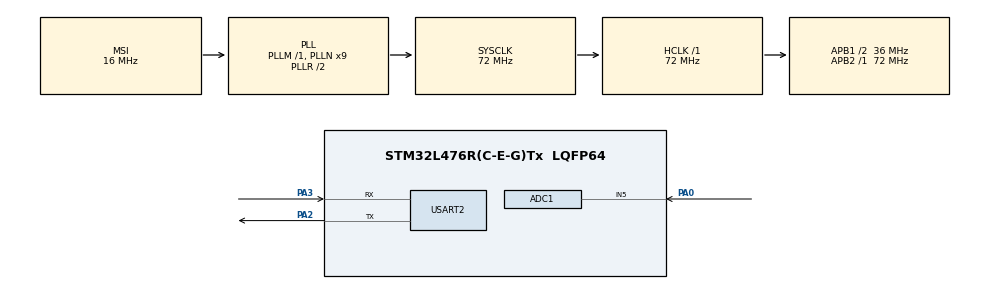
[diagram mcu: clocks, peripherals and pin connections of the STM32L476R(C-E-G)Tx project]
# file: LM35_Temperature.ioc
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ADC1.Channel-0\#ChannelRegularConversion=ADC_CHANNEL_5
ADC1.ClockPrescaler=ADC_CLOCK_ASYNC_DIV2
ADC1.NbrOfConversionFlag=1
ADC1.OffsetNumber-0\#ChannelRegularConversion=ADC_OFFSET_NONE
ADC1.Rank-0\#ChannelRegularConversion=1
ADC1.Resolution=ADC_RESOLUTION_10B
ADC1.SamplingTime-0\#ChannelRegularConversion=ADC_SAMPLETIME_2CYCLES_5
ADC1.master=1
Mcu.Family=STM32L4
Mcu.Name=STM32L476R(C-E-G)Tx
Mcu.Package=LQFP64
NVIC.PriorityGroup=NVIC_PRIORITYGROUP_4
PA0.Signal=ADCx_IN5
PA2.Mode=Asynchronous
PA2.Signal=USART2_TX
PA3.Mode=Asynchronous
PA3.Signal=USART2_RX
ProjectManager.HeapSize=0x200
ProjectManager.StackSize=0x400
ProjectManager.TargetToolchain=STM32CubeIDE
RCC.ADCFreq_Value=64000000
RCC.AHBFreq_Value=72000000
RCC.APB1CLKDivider=RCC_HCLK_DIV2
RCC.APB1Freq_Value=36000000
RCC.APB1TimFreq_Value=72000000
RCC.APB2Freq_Value=72000000
RCC.APB2TimFreq_Value=72000000
RCC.CortexFreq_Value=72000000
RCC.HCLKFreq_Value=72000000
RCC.HSE_VALUE=8000000
RCC.HSI_VALUE=16000000
RCC.LSE_VALUE=32768
RCC.MSIClockRange=RCC_MSIRANGE_8
RCC.MSI_VALUE=16000000
RCC.PLLN=9
RCC.SYSCLKFreq_VALUE=72000000
RCC.SYSCLKSource=RCC_SYSCLKSOURCE_PLLCLK
RCC.USBFreq_Value=64000000
RCC.VCOOutputFreq_Value=144000000
SH.ADCx_IN5.0=ADC1_IN5,IN5-Single-Ended
USART2.VirtualMode-Asynchronous=VM_ASYNC
board=custom

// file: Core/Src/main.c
/* USER CODE BEGIN Header */
/**
  ******************************************************************************
  * @file           : main.c
  * @brief          : Main program body
  ******************************************************************************
  * @attention
  *
  * Copyright (c) 2023 STMicroelectronics.
  * All rights reserved.
  *
  * This software is licensed under terms that can be found in the LICENSE file
  * in the root directory of this software component.
  * If no LICENSE file comes with this software, it is provided AS-IS.
  *
  ******************************************************************************
  */
/* USER CODE END Header */
#include "main.h"

/* USER CODE BEGIN Includes */
#include <stdio.h>
#include <string.h>
/* USER CODE END Includes */

ADC_HandleTypeDef hadc1;

UART_HandleTypeDef huart2;

/* USER CODE BEGIN PV */
uint32_t value_from_sensor = 0;
char log_message[120];
/* USER CODE END PV */

void SystemClock_Config(void);
static void MX_GPIO_Init(void);
static void MX_ADC1_Init(void);
static void MX_USART2_UART_Init(void);
/* USER CODE BEGIN PFP */
void convert_temperature_and_print(uint32_t value_to_convert);
/* USER CODE END PFP */

int main(void)
{

  /* MCU Configuration--------------------------------------------------------*/

  /* Reset of all peripherals, Initializes the Flash interface and the Systick. */
  HAL_Init();

  /* Configure the system clock */
  SystemClock_Config();

  /* Initialize all configured peripherals */
  MX_GPIO_Init();
  MX_ADC1_Init();
  MX_USART2_UART_Init();

  /* Infinite loop */
  /* USER CODE BEGIN WHILE */
  while (1)
  {
	if(HAL_ADC_Start(&hadc1) != HAL_OK) Error_Handler();
	if(HAL_ADC_PollForConversion(&hadc1, 20) != HAL_OK) Error_Handler();
	value_from_sensor = HAL_ADC_GetValue(&hadc1);
	HAL_ADC_Stop(&hadc1);
	if(value_from_sensor > 0)
	{
		convert_temperature_and_print(value_from_sensor);
	}
	HAL_Delay(1000);
    /* USER CODE END WHILE */

  }
}

void SystemClock_Config(void)
{
  RCC_OscInitTypeDef RCC_OscInitStruct = {0};
  RCC_ClkInitTypeDef RCC_ClkInitStruct = {0};

  /** Configure the main internal regulator output voltage
  */
  if (HAL_PWREx_ControlVoltageScaling(PWR_REGULATOR_VOLTAGE_SCALE1) != HAL_OK)
  {
    Error_Handler();
  }

  /** Initializes the RCC Oscillators according to the specified parameters
  * in the RCC_OscInitTypeDef structure.
  */
  RCC_OscInitStruct.OscillatorType = RCC_OSCILLATORTYPE_MSI;
  RCC_OscInitStruct.MSIState = RCC_MSI_ON;
  RCC_OscInitStruct.MSICalibrationValue = 0;
  RCC_OscInitStruct.MSIClockRange = RCC_MSIRANGE_8;
  RCC_OscInitStruct.PLL.PLLState = RCC_PLL_ON;
  RCC_OscInitStruct.PLL.PLLSource = RCC_PLLSOURCE_MSI;
  RCC_OscInitStruct.PLL.PLLM = 1;
  RCC_OscInitStruct.PLL.PLLN = 9;
  RCC_OscInitStruct.PLL.PLLP = RCC_PLLP_DIV7;
  RCC_OscInitStruct.PLL.PLLQ = RCC_PLLQ_DIV2;
  RCC_OscInitStruct.PLL.PLLR = RCC_PLLR_DIV2;
  if (HAL_RCC_OscConfig(&RCC_OscInitStruct) != HAL_OK)
  {
    Error_Handler();
  }

  /** Initializes the CPU, AHB and APB buses clocks
  */
  RCC_ClkInitStruct.ClockType = RCC_CLOCKTYPE_HCLK|RCC_CLOCKTYPE_SYSCLK
                              |RCC_CLOCKTYPE_PCLK1|RCC_CLOCKTYPE_PCLK2;
  RCC_ClkInitStruct.SYSCLKSource = RCC_SYSCLKSOURCE_PLLCLK;
  RCC_ClkInitStruct.AHBCLKDivider = RCC_SYSCLK_DIV1;
  RCC_ClkInitStruct.APB1CLKDivider = RCC_HCLK_DIV2;
  RCC_ClkInitStruct.APB2CLKDivider = RCC_HCLK_DIV1;

  if (HAL_RCC_ClockConfig(&RCC_ClkInitStruct, FLASH_LATENCY_4) != HAL_OK)
  {
    Error_Handler();
  }
}

static void MX_ADC1_Init(void)
{

  ADC_MultiModeTypeDef multimode = {0};
  ADC_ChannelConfTypeDef sConfig = {0};

  /** Common config
  */
  hadc1.Instance = ADC1;
  hadc1.Init.ClockPrescaler = ADC_CLOCK_ASYNC_DIV2;
  hadc1.Init.Resolution = ADC_RESOLUTION_10B;
  hadc1.Init.DataAlign = ADC_DATAALIGN_RIGHT;
  hadc1.Init.ScanConvMode = ADC_SCAN_DISABLE;
  hadc1.Init.EOCSelection = ADC_EOC_SINGLE_CONV;
  hadc1.Init.LowPowerAutoWait = DISABLE;
  hadc1.Init.ContinuousConvMode = DISABLE;
  hadc1.Init.NbrOfConversion = 1;
  hadc1.Init.DiscontinuousConvMode = DISABLE;
  hadc1.Init.ExternalTrigConv = ADC_SOFTWARE_START;
  hadc1.Init.ExternalTrigConvEdge = ADC_EXTERNALTRIGCONVEDGE_NONE;
  hadc1.Init.DMAContinuousRequests = DISABLE;
  hadc1.Init.Overrun = ADC_OVR_DATA_PRESERVED;
  hadc1.Init.OversamplingMode = DISABLE;
  if (HAL_ADC_Init(&hadc1) != HAL_OK)
  {
    Error_Handler();
  }

  /** Configure the ADC multi-mode
  */
  multimode.Mode = ADC_MODE_INDEPENDENT;
  if (HAL_ADCEx_MultiModeConfigChannel(&hadc1, &multimode) != HAL_OK)
  {
    Error_Handler();
  }

  /** Configure Regular Channel
  */
  sConfig.Channel = ADC_CHANNEL_5;
  sConfig.Rank = ADC_REGULAR_RANK_1;
  sConfig.SamplingTime = ADC_SAMPLETIME_2CYCLES_5;
  sConfig.SingleDiff = ADC_SINGLE_ENDED;
  sConfig.OffsetNumber = ADC_OFFSET_NONE;
  sConfig.Offset = 0;
  if (HAL_ADC_ConfigChannel(&hadc1, &sConfig) != HAL_OK)
  {
    Error_Handler();
  }

}

static void MX_USART2_UART_Init(void)
{

  huart2.Instance = USART2;
  huart2.Init.BaudRate = 115200;
  huart2.Init.WordLength = UART_WORDLENGTH_8B;
  huart2.Init.StopBits = UART_STOPBITS_1;
  huart2.Init.Parity = UART_PARITY_NONE;
  huart2.Init.Mode = UART_MODE_TX_RX;
  huart2.Init.HwFlowCtl = UART_HWCONTROL_NONE;
  huart2.Init.OverSampling = UART_OVERSAMPLING_16;
  huart2.Init.OneBitSampling = UART_ONE_BIT_SAMPLE_DISABLE;
  huart2.AdvancedInit.AdvFeatureInit = UART_ADVFEATURE_NO_INIT;
  if (HAL_UART_Init(&huart2) != HAL_OK)
  {
    Error_Handler();
  }

}

static void MX_GPIO_Init(void)
{

  /* GPIO Ports Clock Enable */
  __HAL_RCC_GPIOA_CLK_ENABLE();

}

/* USER CODE BEGIN 4 */
void convert_temperature_and_print(uint32_t value_to_convert)
{
	float temperature = (value_to_convert * 330.0f) / 1023.0f;
	sprintf(log_message, "Temperature: %f C \r\n", temperature);
	HAL_UART_Transmit(&huart2, (uint8_t*)log_message, strlen(log_message), HAL_MAX_DELAY);
	return;
}
/* USER CODE END 4 */

void Error_Handler(void)
{
  __disable_irq();
  while (1)
  {
  }
}
